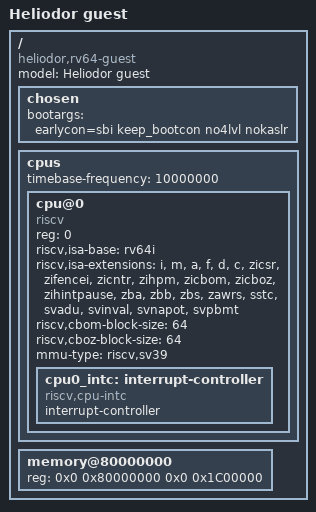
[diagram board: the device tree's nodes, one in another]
/dts-v1/;

/* Phase 11-H5.2b: device tree for the Linux *guest* running under the heliodor
 * bare-metal hypervisor. The guest sees 28 MiB of RAM at guest-physical
 * 0x80000000 (mapped by the G-stage to host 0x80400000). Console is SBI only
 * (earlycon=sbi + keep_bootcon) — the hypervisor forwards DBCN to the real UART
 * — so no UART/PLIC node is exposed to the guest (those device pages are not
 * G-mapped). The CPU advertises sstc, so the guest drives its timer through
 * vstimecmp (Sstc-in-VS), which the hardware delivers as a VS timer interrupt;
 * the hypervisor handles the remaining SBI calls. Single hart. */

/ {
	#address-cells = <2>;
	#size-cells = <2>;
	compatible = "heliodor,rv64-guest";
	model = "Heliodor guest";

	chosen {
		bootargs = "earlycon=sbi keep_bootcon no4lvl nokaslr";
	};

	cpus {
		#address-cells = <1>;
		#size-cells = <0>;
		timebase-frequency = <10000000>;

		cpu@0 {
			device_type = "cpu";
			compatible = "riscv";
			reg = <0>;
			riscv,isa-base = "rv64i";
			riscv,isa-extensions = "i", "m", "a", "f", "d", "c",
				"zicsr", "zifencei", "zicntr", "zihpm",
				"zicbom", "zicboz", "zihintpause",
				"zba", "zbb", "zbs", "zawrs",
				"sstc", "svadu", "svinval", "svnapot", "svpbmt";
			riscv,cbom-block-size = <64>;
			riscv,cboz-block-size = <64>;
			mmu-type = "riscv,sv39";
			status = "okay";

			cpu0_intc: interrupt-controller {
				#interrupt-cells = <1>;
				compatible = "riscv,cpu-intc";
				interrupt-controller;
			};
		};
	};

	memory@80000000 {
		device_type = "memory";
		reg = <0x0 0x80000000 0x0 0x1C00000>;	/* 28 MiB */
	};
};
